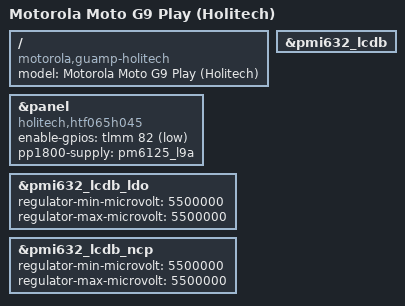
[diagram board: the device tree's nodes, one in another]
// SPDX-License-Identifier: (GPL-2.0+ OR BSD-3-Clause)
/*
 * Copyright (c) 2026, Val Packett <val@packett.cool>
 */

/dts-v1/;

#include "sm6115-motorola-guamp.dtsi"

/ {
	model = "Motorola Moto G9 Play (Holitech)";
	compatible = "motorola,guamp-holitech", "motorola,guamp", "qcom,sm6115";
};

&panel {
	compatible = "holitech,htf065h045", "himax,hx83102";

	enable-gpios = <&tlmm 82 GPIO_ACTIVE_LOW>;
	pp1800-supply = <&pm6125_l9a>;

	status = "okay";
};

&pmi632_lcdb {
	status = "okay";
};

&pmi632_lcdb_ldo {
	regulator-min-microvolt = <5500000>;
	regulator-max-microvolt = <5500000>;
};

&pmi632_lcdb_ncp {
	regulator-min-microvolt = <5500000>;
	regulator-max-microvolt = <5500000>;
};
